# DDR_PHY register map
Registers from a debugger description file.
Registers are 32-bit, access not given, no defined reset value unless marked. A register's access mark holds for its fields unless they carry their own. Addresses are absolute; registers are grouped by the start of their names; lines under a group give offsets from that group; [hi:lo] are bit positions; {n}, {i} and the like mark numbered series; 'fields as' and 'values as' point back to an identical list; <NAME> marks a mode.

## SFR
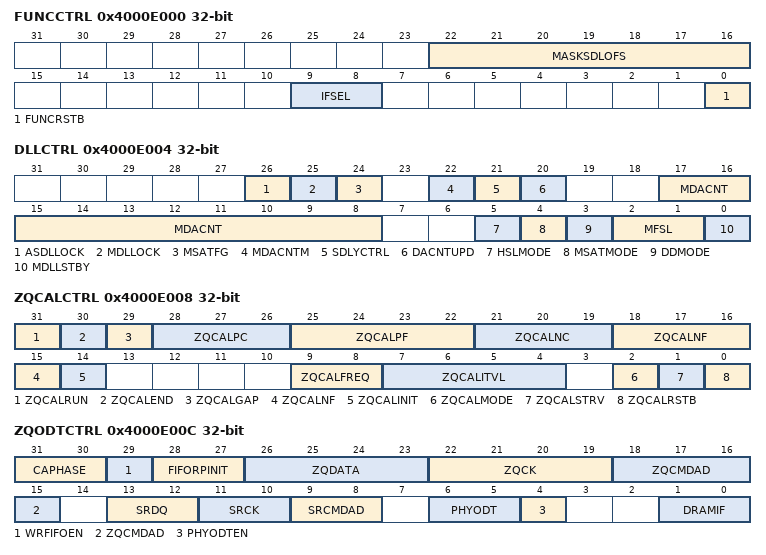
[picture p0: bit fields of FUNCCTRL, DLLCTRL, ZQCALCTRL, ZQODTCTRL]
0x4000E000 FUNCCTRL
  [22:16] MASKSDLOFS, [9:8] IFSEL, [0] FUNCRSTB
0x4000E004 DLLCTRL
  [26] ASDLLOCK, [25] MDLLOCK, [24] MSATFG, [22] MDACNTM, [21] SDLYCTRL, [20] DACNTUPD, [17:8] MDACNT, [5] HSLMODE, [4] MSATMODE, [3] DDMODE, [2:1] MFSL, [0] MDLLSTBY
0x4000E008 ZQCALCTRL
  [31] ZQCALRUN, [30] ZQCALEND, [29] ZQCALGAP, [28:26] ZQCALPC, [25:22] ZQCALPF, [21:19] ZQCALNC, [18:15] ZQCALNF, [14] ZQCALINIT, [9:8] ZQCALFREQ, [7:4] ZQCALITVL, [2] ZQCALMODE, [1] ZQCALSTRV, [0] ZQCALRSTB
0x4000E00C ZQODTCTRL
  [31:30] CAPHASE, [29] WRFIFOEN, [28:27] FIFORPINIT, [26:23] ZQDATA, [22:19] ZQCK, [18:15] ZQCMDAD, [13:12] SRDQ, [11:10] SRCK, [9:8] SRCMDAD, [6:5] PHYODT, [4] PHYODTEN, [1:0] DRAMIF
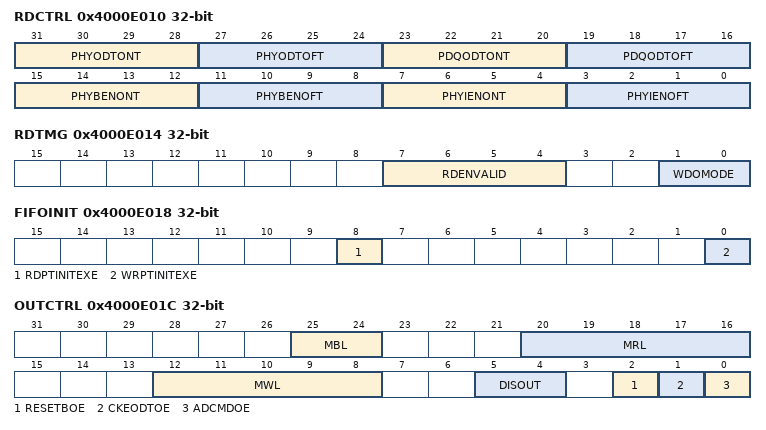
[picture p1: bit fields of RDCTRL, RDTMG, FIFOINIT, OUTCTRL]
0x4000E010 RDCTRL
  [31:28] PHYODTONT, [27:24] PHYODTOFT, [23:20] PDQODTONT, [19:16] PDQODTOFT, [15:12] PHYBENONT, [11:8] PHYBENOFT, [7:4] PHYIENONT, [3:0] PHYIENOFT
0x4000E014 RDTMG
  [7:4] RDENVALID, [1:0] WDOMODE
0x4000E018 FIFOINIT
  [8] RDPTINITEXE, [0] WRPTINITEXE
0x4000E01C OUTCTRL
  [25:24] MBL, [20:16] MRL, [12:8] MWL, [5:4] DISOUT, [2] RESETBOE, [1] CKEODTOE, [0] ADCMDOE
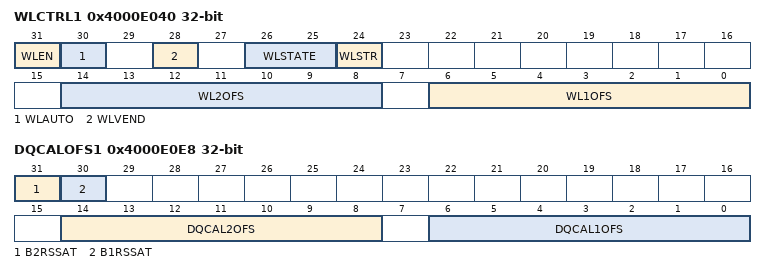
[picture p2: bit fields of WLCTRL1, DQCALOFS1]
0x4000E040 WLCTRL1
  [31] WLEN, [30] WLAUTO, [28] WLVEND, [26:25] WLSTATE, [24] WLSTR, [14:8] WL2OFS, [6:0] WL1OFS
0x4000E0E8 DQCALOFS1
  [31] B2RSSAT, [30] B1RSSAT, [14:8] DQCAL2OFS, [6:0] DQCAL1OFS
